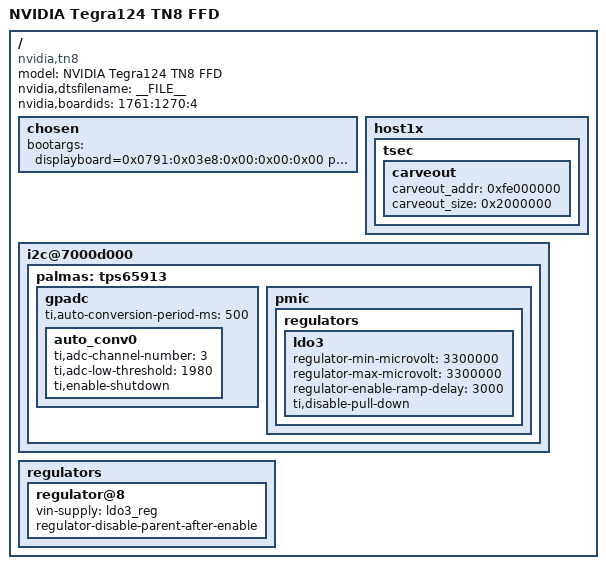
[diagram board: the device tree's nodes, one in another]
/dts-v1/;

#include "tegra124-tn8.dtsi"
#include "tegra124-platforms/tegra124-tn8-emc-p1761-1270-a00.dtsi"
#include "tegra124-platforms/tegra124-tn8-pmic-e1936-1000-a00.dtsi"
#include "tegra124-platforms/tegra124-tn8-sensor-p1761-1270-a03.dtsi"
#include "tegra124-platforms/tegra124-tn8-fixed-e1936-1000-a03.dtsi"
#include "tegra124-platforms/tegra124-tn8-pinmux-p1761-1470-a00.dtsi"
#include "tegra124-platforms/tegra124-tn8-gpio-p1761-1470-a00.dtsi"
#include "tegra124-platforms/tegra124-tn8-keys-p1761-1270-a03.dtsi"
#include "tegra124-platforms/tegra124-tn8-sysedp-p1761-1270-a03.dtsi"
#include "tegra124-platforms/tegra124-tn8-powermon-p1761-a02.dtsi"
#include "tegra124-platforms/tegra124-tn8-dfll-p1761-1270-a03.dtsi"
#include "tegra124-platforms/tegra124-tn8-usb-devices.dtsi"

/ {
	model = "NVIDIA Tegra124 TN8 FFD";
	compatible = "nvidia,tn8", "nvidia,tegra124";
	nvidia,dtsfilename = __FILE__;
	nvidia,boardids = "1761:1270:4";
	#address-cells = <2>;
	#size-cells = <2>;

	chosen {
		bootargs = "displayboard=0x0791:0x03e8:0x00:0x00:0x00 pmuboard=0x06e1:0x04d2:0x04:0x00:0x00";
	};

	host1x {
		tsec {
			carveout {
				carveout_addr = <0xfe000000>;
				carveout_size = <0x2000000>;
			};
		};
	};

	i2c@7000d000 {
		palmas: tps65913 {
			gpadc {
				ti,auto-conversion-period-ms = <500>;
				auto_conv0 {
					ti,adc-channel-number = <3>;
					ti,adc-low-threshold = <1980>;
					ti,enable-shutdown;
				};
			};

			pmic {
				regulators {
					ldo3 {
						regulator-min-microvolt = <3300000>;
						regulator-max-microvolt = <3300000>;
						regulator-enable-ramp-delay = <3000>;
						ti,disable-pull-down;
					};
				};
			};
		};
	};

	regulators {
		regulator@8  {
			vin-supply = <&ldo3_reg>;
			regulator-disable-parent-after-enable;
		};
	};
};

